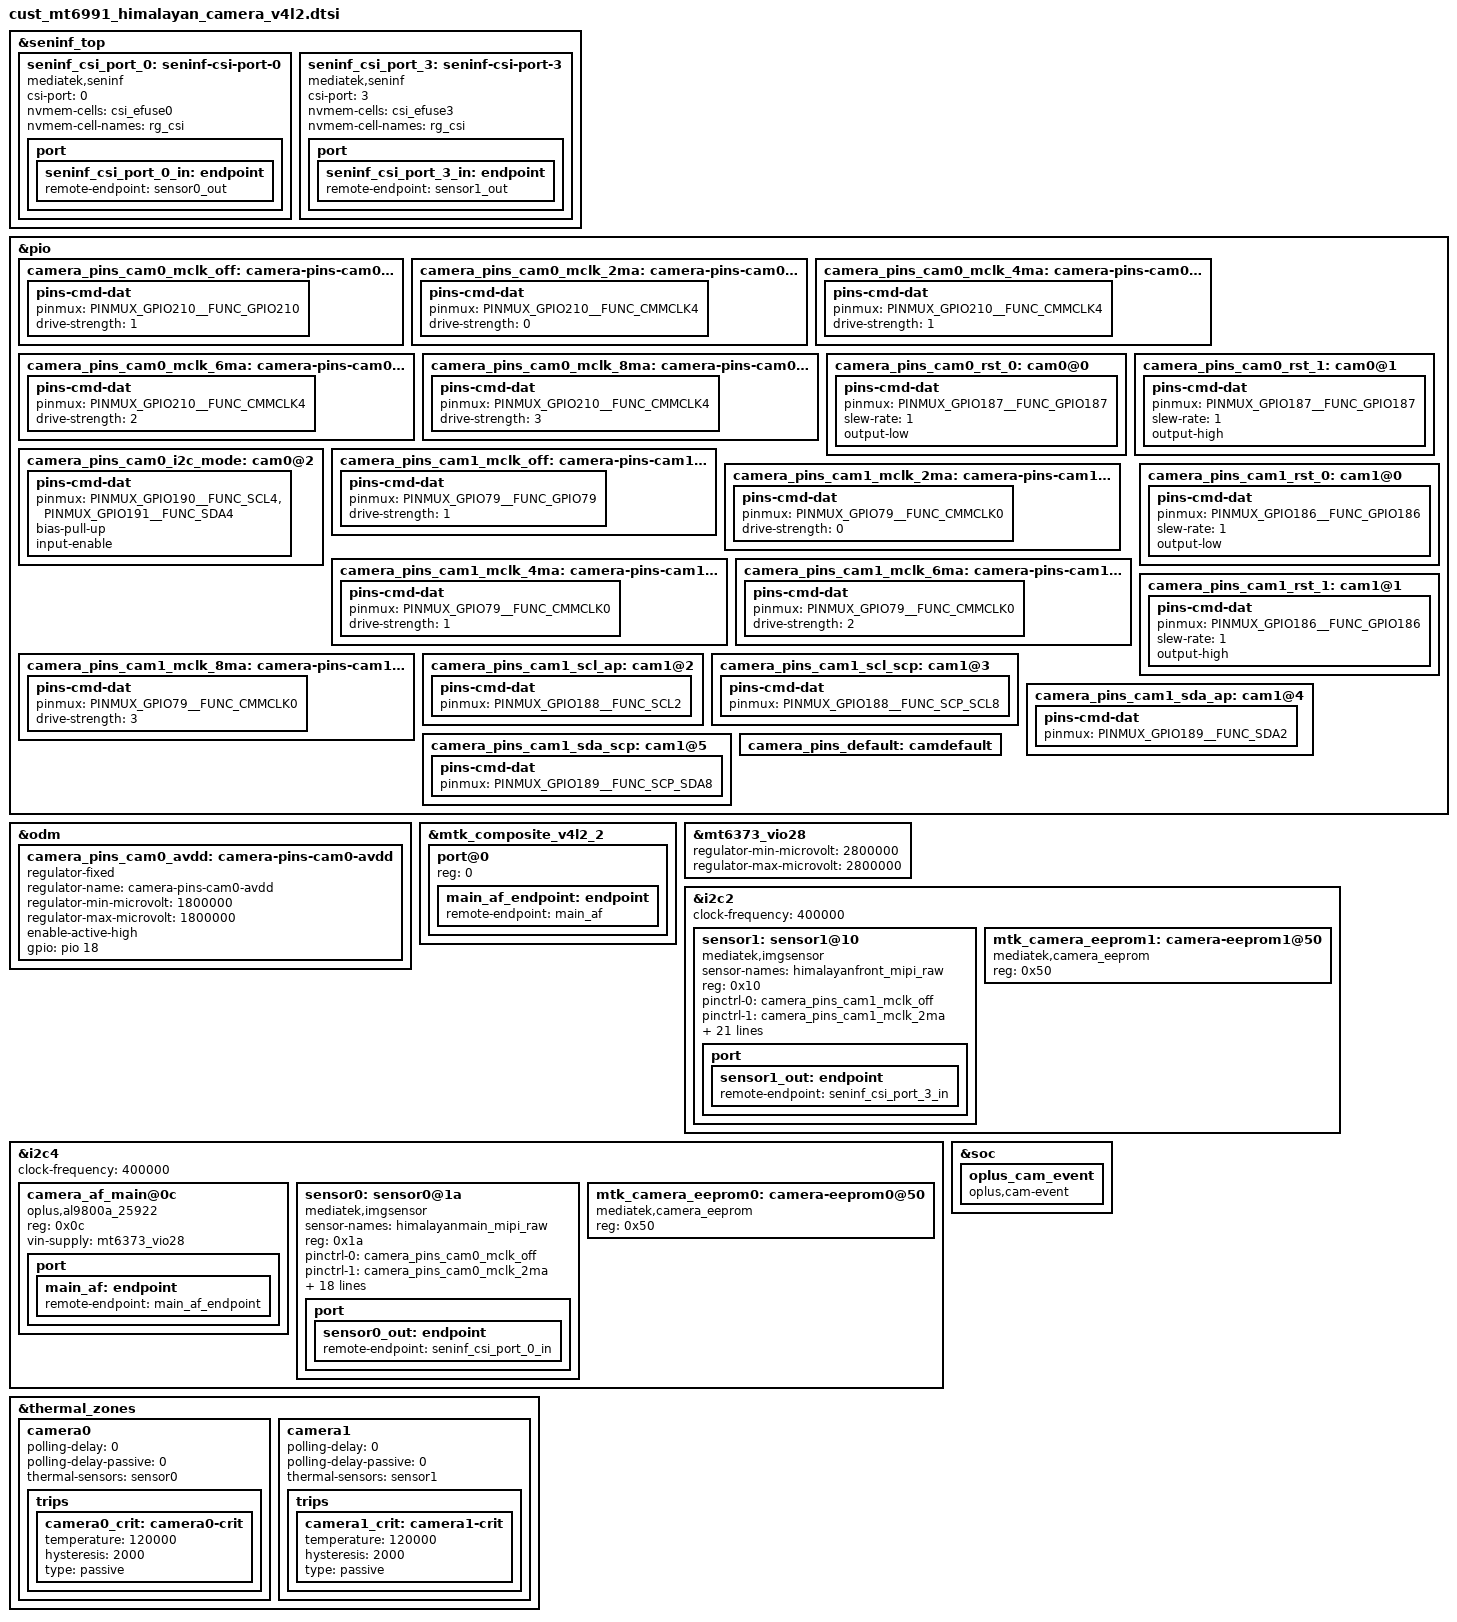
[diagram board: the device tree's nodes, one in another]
// SPDX-License-Identifier: GPL-2.0
/* Copyright (c) 2023 MediaTek Inc. */
#include <dt-bindings/clock/mt6991-clk.h>
#include "mediatek/emira_regulator.dtsi"
// #include "mediatek/mt6373.dtsi"
&seninf_top {
		seninf_csi_port_0: seninf-csi-port-0 {
			compatible = "mediatek,seninf";
			csi-port = "0";

			nvmem-cells = <&csi_efuse0>;
			nvmem-cell-names = "rg_csi";

			port {
				seninf_csi_port_0_in: endpoint {
					remote-endpoint = <&sensor0_out>;
				};
			};
		};
		seninf_csi_port_3: seninf-csi-port-3 {
			compatible = "mediatek,seninf";
			csi-port = "3";

			nvmem-cells = <&csi_efuse3>;
			nvmem-cell-names = "rg_csi";

			port {
				seninf_csi_port_3_in: endpoint {
					remote-endpoint = <&sensor1_out>;
				};
			};
		};
};

/* CAMERA GPIO standardization */
&pio {
	camera_pins_cam0_mclk_off: camera-pins-cam0-mclk-off {
		pins-cmd-dat {
			pinmux = <PINMUX_GPIO210__FUNC_GPIO210>;
			drive-strength = <1>;
		};
	};
	camera_pins_cam0_mclk_2ma: camera-pins-cam0-mclk-2ma {
		pins-cmd-dat {
			pinmux = <PINMUX_GPIO210__FUNC_CMMCLK4>;
			drive-strength = <0>;
		};
	};
	camera_pins_cam0_mclk_4ma: camera-pins-cam0-mclk-4ma {
		pins-cmd-dat {
			pinmux = <PINMUX_GPIO210__FUNC_CMMCLK4>;
			drive-strength = <1>;
		};
	};
	camera_pins_cam0_mclk_6ma: camera-pins-cam0-mclk-6ma {
		pins-cmd-dat {
			pinmux = <PINMUX_GPIO210__FUNC_CMMCLK4>;
			drive-strength = <2>;
		};
	};
	camera_pins_cam0_mclk_8ma: camera-pins-cam0-mclk-8ma {
		pins-cmd-dat {
			pinmux = <PINMUX_GPIO210__FUNC_CMMCLK4>;
			drive-strength = <3>;
		};
	};
	camera_pins_cam0_rst_0: cam0@0 {
		pins-cmd-dat {
			pinmux = <PINMUX_GPIO187__FUNC_GPIO187>;
			slew-rate = <1>;
			output-low;
		};
	};
	camera_pins_cam0_rst_1: cam0@1 {
		pins-cmd-dat {
			pinmux = <PINMUX_GPIO187__FUNC_GPIO187>;
			slew-rate = <1>;
			output-high;
		};
	};
	camera_pins_cam0_i2c_mode: cam0@2 {
		pins-cmd-dat {
			pinmux = <PINMUX_GPIO190__FUNC_SCL4>,
			<PINMUX_GPIO191__FUNC_SDA4>;
			bias-pull-up;
			input-enable;
		};
	};
	camera_pins_cam1_mclk_off: camera-pins-cam1-mclk-off {
		pins-cmd-dat {
			pinmux = <PINMUX_GPIO79__FUNC_GPIO79>;
			drive-strength = <1>;
		};
	};
	camera_pins_cam1_mclk_2ma: camera-pins-cam1-mclk-2ma {
		pins-cmd-dat {
			pinmux = <PINMUX_GPIO79__FUNC_CMMCLK0>;
			drive-strength = <0>;
		};
	};
	camera_pins_cam1_mclk_4ma: camera-pins-cam1-mclk-4ma {
		pins-cmd-dat {
			pinmux = <PINMUX_GPIO79__FUNC_CMMCLK0>;
			drive-strength = <1>;
		};
	};
	camera_pins_cam1_mclk_6ma: camera-pins-cam1-mclk-6ma {
		pins-cmd-dat {
			pinmux = <PINMUX_GPIO79__FUNC_CMMCLK0>;
			drive-strength = <2>;
		};
	};
	camera_pins_cam1_mclk_8ma: camera-pins-cam1-mclk-8ma {
		pins-cmd-dat {
			pinmux = <PINMUX_GPIO79__FUNC_CMMCLK0>;
			drive-strength = <3>;
		};
	};
	camera_pins_cam1_rst_0: cam1@0 {
		pins-cmd-dat {
			pinmux = <PINMUX_GPIO186__FUNC_GPIO186>;
			slew-rate = <1>;
			output-low;
		};
	};
	camera_pins_cam1_rst_1: cam1@1 {
		pins-cmd-dat {
			pinmux = <PINMUX_GPIO186__FUNC_GPIO186>;
			slew-rate = <1>;
			output-high;
		};
	};
	camera_pins_cam1_scl_ap: cam1@2 {
		pins-cmd-dat {
			pinmux = <PINMUX_GPIO188__FUNC_SCL2>;
		};
	};
	camera_pins_cam1_scl_scp: cam1@3 {
		pins-cmd-dat {
			pinmux = <PINMUX_GPIO188__FUNC_SCP_SCL8>;
		};
	};
	camera_pins_cam1_sda_ap: cam1@4 {
		pins-cmd-dat {
			pinmux = <PINMUX_GPIO189__FUNC_SDA2>;
		};
	};
	camera_pins_cam1_sda_scp: cam1@5 {
		pins-cmd-dat {
			pinmux = <PINMUX_GPIO189__FUNC_SCP_SDA8>;
		};
	};
	camera_pins_default: camdefault {
	};
};
/* CAMERA GPIO end */

&odm {
	camera_pins_cam0_avdd: camera-pins-cam0-avdd {
		compatible = "regulator-fixed";
		regulator-name = "camera-pins-cam0-avdd";
		regulator-min-microvolt = <1800000>;
		regulator-max-microvolt = <1800000>;
		enable-active-high;
		gpio = <&pio 18 0x0>;
	};
};

&mtk_composite_v4l2_2 {

	#address-cells = <1>;
	#size-cells = <0>;

	port@0 {
		reg = <0>;
		main_af_endpoint: endpoint {
			remote-endpoint = <&main_af>;
		};
	};
};

/*modify AF Voltage to 2.8V*/
&mt6373_vio28 {
    regulator-min-microvolt = <2800000>;
    regulator-max-microvolt = <2800000>;
};

&i2c2 {
	status = "okay";
	clock-frequency = <400000>;
	#address-cells = <1>;
	#size-cells = <0>;

	sensor1: sensor1@10 {
		compatible = "mediatek,imgsensor";
		sensor-names = "himalayanfront_mipi_raw";
		reg = <0x10>;
		#thermal-sensor-cells = <0>;

		pinctrl-names = "mclk_off",
				"mclk_2mA",
				"mclk_4mA",
				"mclk_6mA",
				"mclk_8mA",
				"rst_low",
				"rst_high",
				"scl_ap",
				"scl_scp",
				"sda_ap",
				"sda_scp";

		pinctrl-0 = <&camera_pins_cam1_mclk_off>;
		pinctrl-1 = <&camera_pins_cam1_mclk_2ma>;
		pinctrl-2 = <&camera_pins_cam1_mclk_4ma>;
		pinctrl-3 = <&camera_pins_cam1_mclk_6ma>;
		pinctrl-4 = <&camera_pins_cam1_mclk_8ma>;
		pinctrl-5 = <&camera_pins_cam1_rst_0>;
		pinctrl-6 = <&camera_pins_cam1_rst_1>;
		pinctrl-7 = <&camera_pins_cam1_scl_ap>;
		pinctrl-8 = <&camera_pins_cam1_scl_scp>;
		pinctrl-9 = <&camera_pins_cam1_sda_ap>;
		pinctrl-10 = <&camera_pins_cam1_sda_scp>;

		avdd-supply = <&mt6373_vtp>;
		dvdd-supply = <&mt6373_vrf12_aif>;
		dovdd-supply = <&mt6373_vrf18_aif>;

		clocks =<&cksys_clk CLK_CK_UNIVPLL_192M_D32>,
			<&cksys_clk CLK_CK_UNIVPLL_192M_D16>,
			<&cksys_clk CLK_CK_F26M_CK_D2>,
			<&cksys_clk CLK_CK_UNIVPLL_192M_D10>,
			<&cksys_clk CLK_CK_UNIVPLL_192M_D8>,
			<&cksys_clk CLK_CK_UNIVPLL_D6_D16>,
			<&cksys_clk CLK_CK_OSC3>,
			<&cksys_clk CLK_CK_UNIVPLL_D6_D8>,
			<&vlp_cksys_clk CLK_VLP_CK_CAMTG0_SEL>;
		clock-names ="6", "12", "13", "19.2",
			"24", "26", "26_ulposc", "52", "mclk";

		status = "okay";
		port {
			sensor1_out: endpoint {
				remote-endpoint = <&seninf_csi_port_3_in>;
			};
		};
	};

	mtk_camera_eeprom1:camera-eeprom1@50 {
		compatible = "mediatek,camera_eeprom";
		reg = <0x50>;
		status = "okay";
	};
};


&i2c4 {
	status = "okay";
	clock-frequency = <400000>;
	#address-cells = <1>;
	#size-cells = <0>;

	camera_af_main@0c {
		compatible = "oplus,al9800a_25922";
		reg = <0x0c>;
		vin-supply = <&mt6373_vio28>;
		port {
			main_af: endpoint {
				remote-endpoint = <&main_af_endpoint>;
			};
		};
	};

	sensor0: sensor0@1a {
		compatible = "mediatek,imgsensor";
		sensor-names = "himalayanmain_mipi_raw";
		reg = <0x1a>;
		#thermal-sensor-cells = <0>;

		pinctrl-names = "mclk_off",
				"mclk_2mA",
				"mclk_4mA",
				"mclk_6mA",
				"mclk_8mA",
				"rst_low",
				"rst_high",
				"default";
		pinctrl-0 = <&camera_pins_cam0_mclk_off>;
		pinctrl-1 = <&camera_pins_cam0_mclk_2ma>;
		pinctrl-2 = <&camera_pins_cam0_mclk_4ma>;
		pinctrl-3 = <&camera_pins_cam0_mclk_6ma>;
		pinctrl-4 = <&camera_pins_cam0_mclk_8ma>;
		pinctrl-5 = <&camera_pins_cam0_rst_0>;
		pinctrl-6 = <&camera_pins_cam0_rst_1>;
		pinctrl-7 = <&camera_pins_cam0_i2c_mode>;

		avdd-supply = <&mt6373_vtp>;
		dvdd-supply = <&mt6373_vrf12_aif>;
		dovdd-supply = <&mt6373_vrf18_aif>;
		afvdd-supply = <&mt6373_vio28>;

		clocks = <&cksys_clk CLK_CK_UNIVPLL_192M_D32>,
			<&cksys_clk CLK_CK_UNIVPLL_192M_D16>,
			<&cksys_clk CLK_CK_F26M_CK_D2>,
			<&cksys_clk CLK_CK_UNIVPLL_192M_D10>,
			<&cksys_clk CLK_CK_UNIVPLL_192M_D8>,
			<&cksys_clk CLK_CK_UNIVPLL_D6_D16>,
			<&cksys_clk CLK_CK_UNIVPLL_D6_D8>,
			<&vlp_cksys_clk CLK_VLP_CK_CAMTG4_SEL>;
		clock-names = "6", "12", "13", "19.2", "24", "26", "52", "mclk";

		status = "okay";

		port {
			sensor0_out: endpoint {
				remote-endpoint = <&seninf_csi_port_0_in>;
			};
		};
	};

	mtk_camera_eeprom0:camera-eeprom0@50 {
		compatible = "mediatek,camera_eeprom";
		reg = <0x50>;
		status = "okay";
	};
};

&thermal_zones {
	camera0: camera0 {
		polling-delay = <0>; /* milliseconds */
		polling-delay-passive = <0>; /* milliseconds */
		thermal-sensors = <&sensor0>;
		trips {
			camera0_crit: camera0-crit {
				temperature = <120000>;
				hysteresis = <2000>;
				type = "passive";
			};
		};
	};
	camera1: camera1 {
		polling-delay = <0>; /* milliseconds */
		polling-delay-passive = <0>; /* milliseconds */
		thermal-sensors = <&sensor1>;
		trips {
			camera1_crit: camera1-crit {
				temperature = <120000>;
				hysteresis = <2000>;
				type = "passive";
			};
		};
	};
};

&soc {
	//#ifdef OPLUS_FEATURE_CAMERA_COMMON
	oplus_cam_event:oplus_cam_event {
		compatible = "oplus,cam-event";
	};
	//#endif /* OPLUS_FEATURE_CAMERA_COMMON */
};
